AUTOSAR XML (schema 00048)
package /ComponentTypes
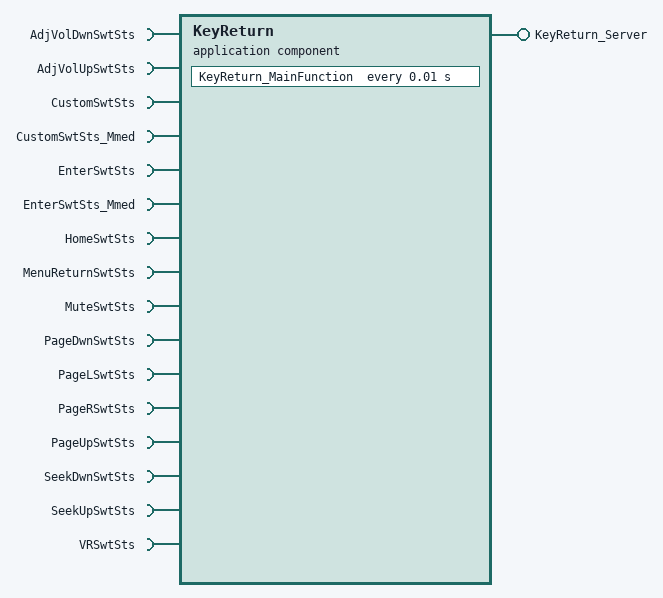
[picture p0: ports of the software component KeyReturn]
  application sw component type KeyReturn
    provide port KeyReturn_Server: provided-interface=KeyReturn_Server
      provided-com-specs:
        operation=disanle, queue-length=1
        operation=enable, queue-length=1
        operation=register, queue-length=1
        operation=remove, queue-length=1
        operation=State, queue-length=1
    16 x require port:
      AdjVolDwnSwtSts: nonqueued-receiver-com-spec{data-element=AdjVolDwnSwtSts, alive-timeout=0.5, enable-update=true, filter=data-filter-type=ALWAYS, handle-never-received=true, init-value=0}, required-interface=AdjVolDwnSwtSts
      AdjVolUpSwtSts: nonqueued-receiver-com-spec{data-element=AdjVolUpSwtSts, alive-timeout=0.5, enable-update=true, filter=data-filter-type=ALWAYS, handle-never-received=true, init-value=0}, required-interface=AdjVolUpSwtSts
      CustomSwtSts: nonqueued-receiver-com-spec{data-element=CustomSwtSts, alive-timeout=0.5, enable-update=true, filter=data-filter-type=ALWAYS, handle-never-received=true, init-value=0}, required-interface=CustomSwtSts
      CustomSwtSts_Mmed: nonqueued-receiver-com-spec{data-element=CustomSwtSts_Mmed, enable-update=true, filter=data-filter-type=ALWAYS, handle-never-received=true, init-value=0}, required-interface=CustomSwtSts_Mmed
      EnterSwtSts: nonqueued-receiver-com-spec{data-element=EnterSwtSts, alive-timeout=0.5, enable-update=true, filter=data-filter-type=ALWAYS, handle-never-received=true, init-value=0}, required-interface=EnterSwtSts
      EnterSwtSts_Mmed: nonqueued-receiver-com-spec{data-element=EnterSwtSts_Mmed, alive-timeout=0.5, enable-update=true, filter=data-filter-type=ALWAYS, handle-never-received=true, init-value=0}, required-interface=EnterSwtSts_Mmed
      HomeSwtSts: nonqueued-receiver-com-spec{data-element=HomeSwtSts, alive-timeout=0.5, enable-update=true, filter=data-filter-type=ALWAYS, handle-never-received=true, init-value=0}, required-interface=HomeSwtSts
      MenuReturnSwtSts: nonqueued-receiver-com-spec{data-element=MenuReturnSwtSts, alive-timeout=0.5, enable-update=true, filter=data-filter-type=ALWAYS, handle-never-received=true, init-value=0}, required-interface=MenuReturnSwtSts
      MuteSwtSts: nonqueued-receiver-com-spec{data-element=MuteSwtSts, alive-timeout=0.5, enable-update=true, filter=data-filter-type=ALWAYS, handle-never-received=true, init-value=0}, required-interface=MuteSwtSts
      PageDwnSwtSts: nonqueued-receiver-com-spec{data-element=PageDwnSwtSts, alive-timeout=0.5, enable-update=true, filter=data-filter-type=ALWAYS, handle-never-received=true, init-value=0}, required-interface=PageDwnSwtSts
      PageLSwtSts: nonqueued-receiver-com-spec{data-element=PageLSwtSts, alive-timeout=0.5, enable-update=true, filter=data-filter-type=ALWAYS, handle-never-received=true, init-value=0}, required-interface=PageLSwtSts
      PageRSwtSts: nonqueued-receiver-com-spec{data-element=PageRSwtSts, alive-timeout=0.5, enable-update=true, filter=data-filter-type=ALWAYS, handle-never-received=true, init-value=0}, required-interface=PageRSwtSts
      PageUpSwtSts: nonqueued-receiver-com-spec{data-element=PageUpSwtSts, alive-timeout=0.5, enable-update=true, filter=data-filter-type=ALWAYS, handle-never-received=true, init-value=0}, required-interface=PageUpSwtSts
      SeekDwnSwtSts: nonqueued-receiver-com-spec{data-element=SeekDwnSwtSts, alive-timeout=0.5, enable-update=true, filter=data-filter-type=ALWAYS, handle-never-received=true, init-value=0}, required-interface=SeekDwnSwtSts
      SeekUpSwtSts: nonqueued-receiver-com-spec{data-element=SeekUpSwtSts, alive-timeout=0.5, enable-update=true, filter=data-filter-type=ALWAYS, handle-never-received=true, init-value=0}, required-interface=SeekUpSwtSts
      VRSwtSts: nonqueued-receiver-com-spec{data-element=VRSwtSts, alive-timeout=0.5, enable-update=true, filter=data-filter-type=ALWAYS, handle-never-received=true, init-value=0}, required-interface=VRSwtSts
    behavior KeyReturn_InternalBehavior
      init event KeyReturn_InitEvent: start-on-event=KeyReturn_Init
      timing event TMT_KeyReturn_MainFunction: start-on-event=KeyReturn_MainFunction, period=0.01
      5 x operation invoked event:
        OIT_Runnable_1_KeyReturn_Server_disanle: start-on-event=KeyReturn_Server_disanle, operation=KeyReturn_Server.disanle
        OIT_Runnable_2_KeyReturn_Server_enable: start-on-event=KeyReturn_Server_enable, operation=KeyReturn_Server.enable
        OIT_Runnable_3_KeyReturn_Server_register: start-on-event=KeyReturn_Server_register, operation=KeyReturn_Server.register
        OIT_Runnable_4_KeyReturn_Server_remove: start-on-event=KeyReturn_Server_remove, operation=KeyReturn_Server.remove
        OIT_Runnable_KeyReturn_Server_State: start-on-event=KeyReturn_Server_State, operation=KeyReturn_Server.State
      7 x runnable:
        KeyReturn_Init
          data-receive-point-by-arguments:
            16 x access:
              REC_AdjVolDwnSwtSts_AdjVolDwnSwtSts: accessed-variable=AdjVolDwnSwtSts.AdjVolDwnSwtSts
              REC_AdjVolUpSwtSts_AdjVolUpSwtSts: accessed-variable=AdjVolUpSwtSts.AdjVolUpSwtSts
              REC_CustomSwtSts_CustomSwtSts: accessed-variable=CustomSwtSts.CustomSwtSts
              REC_CustomSwtSts_Mmed_CustomSwtSts_Mmed: accessed-variable=CustomSwtSts_Mmed.CustomSwtSts_Mmed
              REC_EnterSwtSts_EnterSwtSts: accessed-variable=EnterSwtSts.EnterSwtSts
              REC_EnterSwtSts_Mmed_EnterSwtSts_Mmed: accessed-variable=EnterSwtSts_Mmed.EnterSwtSts_Mmed
              REC_HomeSwtSts_HomeSwtSts: accessed-variable=HomeSwtSts.HomeSwtSts
              REC_MenuReturnSwtSts_MenuReturnSwtSts: accessed-variable=MenuReturnSwtSts.MenuReturnSwtSts
              REC_MuteSwtSts_MuteSwtSts: accessed-variable=MuteSwtSts.MuteSwtSts
              REC_PageDwnSwtSts_PageDwnSwtSts: accessed-variable=PageDwnSwtSts.PageDwnSwtSts
              REC_PageLSwtSts_PageLSwtSts: accessed-variable=PageLSwtSts.PageLSwtSts
              REC_PageRSwtSts_PageRSwtSts: accessed-variable=PageRSwtSts.PageRSwtSts
              REC_PageUpSwtSts_PageUpSwtSts: accessed-variable=PageUpSwtSts.PageUpSwtSts
              REC_SeekDwnSwtSts_SeekDwnSwtSts: accessed-variable=SeekDwnSwtSts.SeekDwnSwtSts
              REC_SeekUpSwtSts_SeekUpSwtSts: accessed-variable=SeekUpSwtSts.SeekUpSwtSts
              REC_VRSwtSts_VRSwtSts: accessed-variable=VRSwtSts.VRSwtSts
        KeyReturn_MainFunction
          data-receive-point-by-arguments:
            16 x access:
              REC_AdjVolDwnSwtSts_AdjVolDwnSwtSts: accessed-variable=AdjVolDwnSwtSts.AdjVolDwnSwtSts
              REC_AdjVolUpSwtSts_AdjVolUpSwtSts: accessed-variable=AdjVolUpSwtSts.AdjVolUpSwtSts
              REC_CustomSwtSts_CustomSwtSts: accessed-variable=CustomSwtSts.CustomSwtSts
              REC_CustomSwtSts_Mmed_CustomSwtSts_Mmed: accessed-variable=CustomSwtSts_Mmed.CustomSwtSts_Mmed
              REC_EnterSwtSts_EnterSwtSts: accessed-variable=EnterSwtSts.EnterSwtSts
              REC_EnterSwtSts_Mmed_EnterSwtSts_Mmed: accessed-variable=EnterSwtSts_Mmed.EnterSwtSts_Mmed
              REC_HomeSwtSts_HomeSwtSts: accessed-variable=HomeSwtSts.HomeSwtSts
              REC_MenuReturnSwtSts_MenuReturnSwtSts: accessed-variable=MenuReturnSwtSts.MenuReturnSwtSts
              REC_MuteSwtSts_MuteSwtSts: accessed-variable=MuteSwtSts.MuteSwtSts
              REC_PageDwnSwtSts_PageDwnSwtSts: accessed-variable=PageDwnSwtSts.PageDwnSwtSts
              REC_PageLSwtSts_PageLSwtSts: accessed-variable=PageLSwtSts.PageLSwtSts
              REC_PageRSwtSts_PageRSwtSts: accessed-variable=PageRSwtSts.PageRSwtSts
              REC_PageUpSwtSts_PageUpSwtSts: accessed-variable=PageUpSwtSts.PageUpSwtSts
              REC_SeekDwnSwtSts_SeekDwnSwtSts: accessed-variable=SeekDwnSwtSts.SeekDwnSwtSts
              REC_SeekUpSwtSts_SeekUpSwtSts: accessed-variable=SeekUpSwtSts.SeekUpSwtSts
              REC_VRSwtSts_VRSwtSts: accessed-variable=VRSwtSts.VRSwtSts
        KeyReturn_Server_disanle
        KeyReturn_Server_enable
        KeyReturn_Server_register
        KeyReturn_Server_remove
        KeyReturn_Server_State
  swc implementation KeyReturn_Implementation: behavior=KeyReturn_InternalBehavior
    code-descriptors:
      code Default: artifact-descriptors=autosar-engineering-object=category=SWSRC
